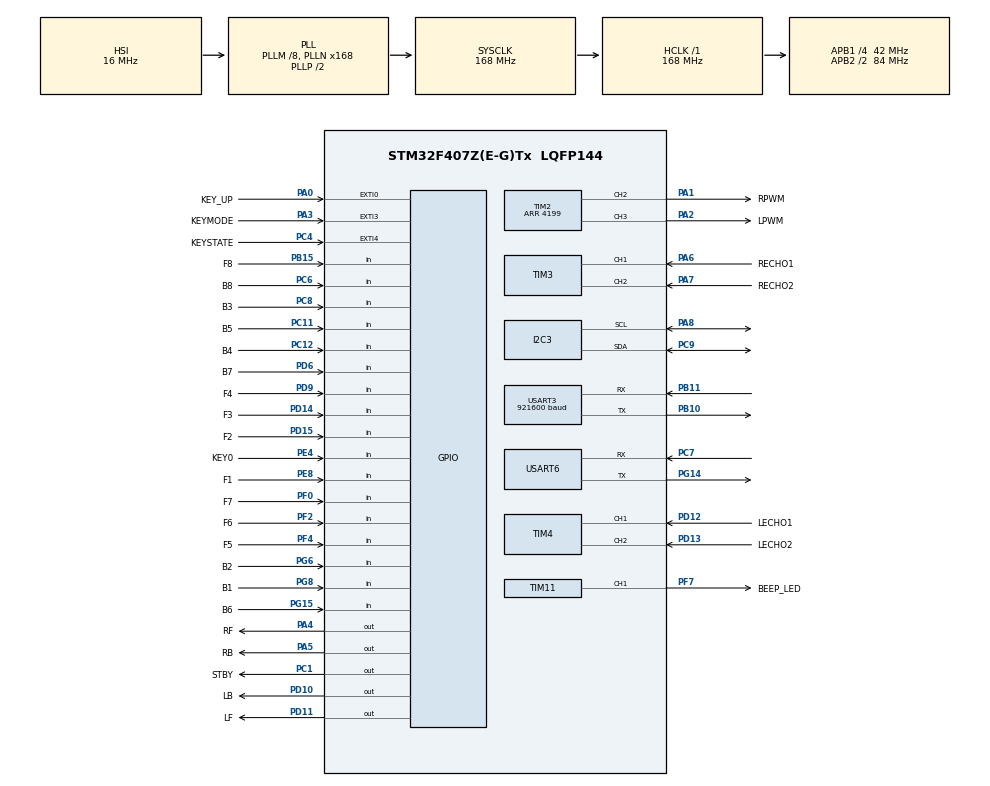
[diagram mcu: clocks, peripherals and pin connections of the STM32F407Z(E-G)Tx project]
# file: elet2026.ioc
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Dma.I2C3_TX.0.Direction=DMA_MEMORY_TO_PERIPH
Dma.I2C3_TX.0.FIFOMode=DMA_FIFOMODE_DISABLE
Dma.I2C3_TX.0.Instance=DMA1_Stream4
Dma.I2C3_TX.0.MemDataAlignment=DMA_MDATAALIGN_BYTE
Dma.I2C3_TX.0.MemInc=DMA_MINC_ENABLE
Dma.I2C3_TX.0.Mode=DMA_NORMAL
Dma.I2C3_TX.0.PeriphDataAlignment=DMA_PDATAALIGN_BYTE
Dma.I2C3_TX.0.PeriphInc=DMA_PINC_DISABLE
Dma.I2C3_TX.0.Priority=DMA_PRIORITY_LOW
Dma.Request0=I2C3_TX
Dma.Request1=USART3_RX
Dma.Request2=USART6_TX
Dma.Request3=USART6_RX
Dma.USART3_RX.1.Direction=DMA_PERIPH_TO_MEMORY
Dma.USART3_RX.1.FIFOMode=DMA_FIFOMODE_DISABLE
Dma.USART3_RX.1.Instance=DMA1_Stream1
Dma.USART3_RX.1.MemDataAlignment=DMA_MDATAALIGN_BYTE
Dma.USART3_RX.1.MemInc=DMA_MINC_ENABLE
Dma.USART3_RX.1.Mode=DMA_NORMAL
Dma.USART3_RX.1.PeriphDataAlignment=DMA_PDATAALIGN_BYTE
Dma.USART3_RX.1.PeriphInc=DMA_PINC_DISABLE
Dma.USART3_RX.1.Priority=DMA_PRIORITY_HIGH
Dma.USART6_RX.3.Direction=DMA_PERIPH_TO_MEMORY
Dma.USART6_RX.3.FIFOMode=DMA_FIFOMODE_DISABLE
Dma.USART6_RX.3.Instance=DMA2_Stream1
Dma.USART6_RX.3.MemDataAlignment=DMA_MDATAALIGN_BYTE
Dma.USART6_RX.3.MemInc=DMA_MINC_ENABLE
Dma.USART6_RX.3.Mode=DMA_NORMAL
Dma.USART6_RX.3.PeriphDataAlignment=DMA_PDATAALIGN_BYTE
Dma.USART6_RX.3.PeriphInc=DMA_PINC_DISABLE
Dma.USART6_RX.3.Priority=DMA_PRIORITY_LOW
Dma.USART6_TX.2.Direction=DMA_MEMORY_TO_PERIPH
Dma.USART6_TX.2.FIFOMode=DMA_FIFOMODE_DISABLE
Dma.USART6_TX.2.Instance=DMA2_Stream6
Dma.USART6_TX.2.MemDataAlignment=DMA_MDATAALIGN_BYTE
Dma.USART6_TX.2.MemInc=DMA_MINC_ENABLE
Dma.USART6_TX.2.Mode=DMA_NORMAL
Dma.USART6_TX.2.PeriphDataAlignment=DMA_PDATAALIGN_BYTE
Dma.USART6_TX.2.PeriphInc=DMA_PINC_DISABLE
Dma.USART6_TX.2.Priority=DMA_PRIORITY_LOW
FREERTOS.BinarySemaphores01=IMUdatadoneBinarySem,Dynamic,NULL
FREERTOS.Queues01=Controlqueue,1,6,1,Dynamic,NULL,NULL;dataToLCDQueue,1,80,1,Dynamic,NULL,NULL;paramQueue,1,68,1,Dynamic,NULL,NULL;paramtocontroltask,1,64,1,Dynamic,NULL,NULL
FREERTOS.Tasks01=defaultTask,44,256,StartDefaultTask,Default,NULL,Dynamic,NULL,NULL;PID,28,512,StartPIDTask,As external,NULL,Dynamic,NULL,NULL;controlTask,13,512,StartcontrolTask,As external,NULL,Dynamic,NULL,NULL;displayTask,8,512,StartdisplayTask,As external,NULL,Dynamic,NULL,NULL
I2C3.I2C_Mode=I2C_Fast
Mcu.Family=STM32F4
Mcu.Name=STM32F407Z(E-G)Tx
Mcu.Package=LQFP144
NVIC.DMA1_Stream1_IRQn=true\:5\:0\:false\:false\:true\:true\:false\:true
NVIC.DMA1_Stream4_IRQn=true\:5\:0\:false\:false\:true\:true\:false\:true
NVIC.DMA2_Stream1_IRQn=true\:5\:0\:false\:false\:true\:true\:false\:true
NVIC.DMA2_Stream6_IRQn=true\:5\:0\:false\:false\:true\:true\:false\:true
NVIC.EXTI0_IRQn=true\:5\:0\:false\:false\:true\:true\:true\:true
NVIC.EXTI3_IRQn=true\:5\:0\:false\:false\:true\:true\:true\:true
NVIC.EXTI4_IRQn=true\:5\:0\:false\:false\:true\:true\:true\:true
NVIC.I2C3_ER_IRQn=true\:5\:0\:false\:false\:true\:true\:true\:true
NVIC.I2C3_EV_IRQn=true\:5\:0\:false\:false\:true\:true\:true\:true
NVIC.PriorityGroup=NVIC_PRIORITYGROUP_4
NVIC.TIM6_DAC_IRQn=true\:15\:0\:false\:false\:true\:false\:false\:true
NVIC.TimeBase=TIM6_DAC_IRQn
NVIC.TimeBaseIP=TIM6
NVIC.USART3_IRQn=true\:5\:0\:false\:false\:true\:true\:true\:true
NVIC.USART6_IRQn=true\:5\:0\:false\:false\:true\:true\:true\:true
PA0-WKUP.GPIO_Label=KEY_UP
PA0-WKUP.GPIO_ModeDefaultEXTI=GPIO_MODE_IT_RISING
PA0-WKUP.GPIO_PuPd=GPIO_PULLDOWN
PA0-WKUP.Signal=GPXTI0
PA1.GPIO_Label=RPWM
PA1.Signal=S_TIM2_CH2
PA2.GPIO_Label=LPWM
PA2.Signal=S_TIM2_CH3
PA3.GPIO_Label=KEYMODE
PA3.Signal=GPXTI3
PA4.GPIO_Label=RF
PA4.Signal=GPIO_Output
PA5.GPIO_Label=RB
PA5.Signal=GPIO_Output
PA6.GPIO_Label=RECHO1
PA6.Signal=S_TIM3_CH1
PA7.GPIO_Label=RECHO2
PA7.Signal=S_TIM3_CH2
PA8.Mode=I2C
PA8.Signal=I2C3_SCL
PB10.Mode=Asynchronous
PB10.Signal=USART3_TX
PB11.Mode=Asynchronous
PB11.Signal=USART3_RX
PB15.GPIO_Label=F8
PB15.Signal=GPIO_Input
PC1.GPIO_Label=STBY
PC1.Signal=GPIO_Output
PC11.GPIO_Label=B5
PC11.Signal=GPIO_Input
PC12.GPIO_Label=B4
PC12.Signal=GPIO_Input
PC4.GPIO_Label=KEYSTATE
PC4.Signal=GPXTI4
PE4.GPIO_Label=KEY0
PE4.GPIO_PuPd=GPIO_PULLUP
PE4.Signal=GPIO_Input
PC6.GPIO_Label=B8
PC6.Signal=GPIO_Input
PC7.Mode=Asynchronous
PC7.Signal=USART6_RX
PC8.GPIO_Label=B3
PC8.Signal=GPIO_Input
PC9.Mode=I2C
PC9.Signal=I2C3_SDA
PD10.GPIO_Label=LB
PD10.Signal=GPIO_Output
PD11.GPIO_Label=LF
PD11.Signal=GPIO_Output
PD12.GPIO_Label=LECHO1
PD12.Signal=S_TIM4_CH1
PD13.GPIO_Label=LECHO2
PD13.Signal=S_TIM4_CH2
PD14.GPIO_Label=F3
PD14.Signal=GPIO_Input
PD15.GPIO_Label=F2
PD15.Signal=GPIO_Input
PD6.GPIO_Label=B7
PD6.Signal=GPIO_Input
PD9.GPIO_Label=F4
PD9.Signal=GPIO_Input
PE8.GPIO_Label=F1
PE8.Signal=GPIO_Input
PF0.GPIO_Label=F7
PF0.Signal=GPIO_Input
PF2.GPIO_Label=F6
PF2.Signal=GPIO_Input
PF4.GPIO_Label=F5
PF4.Signal=GPIO_Input
PF7.GPIO_Label=BEEP_LED
PF7.Signal=S_TIM11_CH1
PG14.Mode=Asynchronous
PG14.Signal=USART6_TX
PG15.GPIO_Label=B6
PG15.Signal=GPIO_Input
PG6.GPIO_Label=B2
PG6.Signal=GPIO_Input
PG8.GPIO_Label=B1
PG8.Signal=GPIO_Input
PH0-OSC_IN.Mode=HSE-External-Oscillator
PH0-OSC_IN.Signal=RCC_OSC_IN
PH1-OSC_OUT.Mode=HSE-External-Oscillator
PH1-OSC_OUT.Signal=RCC_OSC_OUT
ProjectManager.HeapSize=0x200
ProjectManager.StackSize=0x400
ProjectManager.TargetToolchain=MDK-ARM V5.32
RCC.48MHZClocksFreq_Value=84000000
RCC.AHBFreq_Value=168000000
RCC.APB1CLKDivider=RCC_HCLK_DIV4
RCC.APB1Freq_Value=42000000
RCC.APB1TimFreq_Value=84000000
RCC.APB2CLKDivider=RCC_HCLK_DIV2
RCC.APB2Freq_Value=84000000
RCC.APB2TimFreq_Value=168000000
RCC.CortexFreq_Value=168000000
RCC.HCLKFreq_Value=168000000
RCC.HSE_VALUE=8000000
RCC.HSI_VALUE=16000000
RCC.LSE_VALUE=32768
RCC.PLLM=8
RCC.PLLN=168
RCC.SYSCLKFreq_VALUE=168000000
RCC.SYSCLKSource=RCC_SYSCLKSOURCE_PLLCLK
RCC.VCOOutputFreq_Value=336000000
SH.S_TIM11_CH1.0=TIM11_CH1,PWM Generation1 CH1
SH.S_TIM2_CH2.0=TIM2_CH2,PWM Generation2 CH2
SH.S_TIM2_CH3.0=TIM2_CH3,PWM Generation3 CH3
SH.S_TIM3_CH1.0=TIM3_CH1,Encoder_Interface
SH.S_TIM3_CH2.0=TIM3_CH2,Encoder_Interface
SH.S_TIM4_CH1.0=TIM4_CH1,Encoder_Interface
SH.S_TIM4_CH2.0=TIM4_CH2,Encoder_Interface
TIM11.Channel=TIM_CHANNEL_1
TIM2.Channel-PWM\ Generation2\ CH2=TIM_CHANNEL_2
TIM2.Channel-PWM\ Generation3\ CH3=TIM_CHANNEL_3
TIM2.Period=4199
TIM3.EncoderMode=TIM_ENCODERMODE_TI12
TIM4.EncoderMode=TIM_ENCODERMODE_TI12
USART3.BaudRate=921600
USART3.VirtualMode=VM_ASYNC
USART6.VirtualMode=VM_ASYNC
VP_FREERTOS_VS_CMSIS_V2.Mode=CMSIS_V2
VP_SYS_VS_tim6.Mode=TIM6
VP_TIM11_VS_ClockSourceINT.Mode=Enable_Timer
VP_TIM2_VS_ClockSourceINT.Mode=Internal
board=custom

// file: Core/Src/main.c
/* USER CODE BEGIN Header */
/**
  ******************************************************************************
  * @file           : main.c
  * @brief          : Main program body
  ******************************************************************************
  * @attention
  *
  * <h2><center>&copy; Copyright (c) 2026 STMicroelectronics.
  * All rights reserved.</center></h2>
  *
  * This software component is licensed by ST under Ultimate Liberty license
  * SLA0044, the "License"; You may not use this file except in compliance with
  * the License. You may obtain a copy of the License at:
  *                             www.st.com/SLA0044
  *
  ******************************************************************************
  */
/* USER CODE END Header */
#include "main.h"
#include "cmsis_os.h"
#include "dma.h"
#include "i2c.h"
#include "tim.h"
#include "usart.h"
#include "gpio.h"

void SystemClock_Config(void);
void MX_FREERTOS_Init(void);

int main(void)
{

  /* MCU Configuration--------------------------------------------------------*/

  /* Reset of all peripherals, Initializes the Flash interface and the Systick. */
  HAL_Init();

  /* Configure the system clock */
  SystemClock_Config();

  /* Initialize all configured peripherals */
  MX_GPIO_Init();
  MX_DMA_Init();
  MX_TIM3_Init();
  MX_TIM4_Init();
  MX_TIM2_Init();
  MX_I2C3_Init();
  MX_USART3_UART_Init();
  MX_TIM11_Init();
  MX_USART6_UART_Init();

  /* Init scheduler */
  osKernelInitialize();  /* Call init function for freertos objects (in freertos.c) */
  MX_FREERTOS_Init();
  /* Start scheduler */
  osKernelStart();

  /* We should never get here as control is now taken by the scheduler */
  /* Infinite loop */
  while (1)
  {

  }
}

void SystemClock_Config(void)
{
  RCC_OscInitTypeDef RCC_OscInitStruct = {0};
  RCC_ClkInitTypeDef RCC_ClkInitStruct = {0};

  /** Configure the main internal regulator output voltage
  */
  __HAL_RCC_PWR_CLK_ENABLE();
  __HAL_PWR_VOLTAGESCALING_CONFIG(PWR_REGULATOR_VOLTAGE_SCALE1);
  /** Initializes the RCC Oscillators according to the specified parameters
  * in the RCC_OscInitTypeDef structure.
  */
  RCC_OscInitStruct.OscillatorType = RCC_OSCILLATORTYPE_HSI;
  RCC_OscInitStruct.HSIState = RCC_HSI_ON;
  RCC_OscInitStruct.HSICalibrationValue = RCC_HSICALIBRATION_DEFAULT;
  RCC_OscInitStruct.PLL.PLLState = RCC_PLL_ON;
  RCC_OscInitStruct.PLL.PLLSource = RCC_PLLSOURCE_HSI;
  RCC_OscInitStruct.PLL.PLLM = 8;
  RCC_OscInitStruct.PLL.PLLN = 168;
  RCC_OscInitStruct.PLL.PLLP = RCC_PLLP_DIV2;
  RCC_OscInitStruct.PLL.PLLQ = 4;
  if (HAL_RCC_OscConfig(&RCC_OscInitStruct) != HAL_OK)
  {
    Error_Handler();
  }
  /** Initializes the CPU, AHB and APB buses clocks
  */
  RCC_ClkInitStruct.ClockType = RCC_CLOCKTYPE_HCLK|RCC_CLOCKTYPE_SYSCLK
                              |RCC_CLOCKTYPE_PCLK1|RCC_CLOCKTYPE_PCLK2;
  RCC_ClkInitStruct.SYSCLKSource = RCC_SYSCLKSOURCE_PLLCLK;
  RCC_ClkInitStruct.AHBCLKDivider = RCC_SYSCLK_DIV1;
  RCC_ClkInitStruct.APB1CLKDivider = RCC_HCLK_DIV4;
  RCC_ClkInitStruct.APB2CLKDivider = RCC_HCLK_DIV2;

  if (HAL_RCC_ClockConfig(&RCC_ClkInitStruct, FLASH_LATENCY_5) != HAL_OK)
  {
    Error_Handler();
  }
}

void HAL_TIM_PeriodElapsedCallback(TIM_HandleTypeDef *htim)
{
  if (htim->Instance == TIM6) {
    HAL_IncTick();
  }
}

void Error_Handler(void)
{
  __disable_irq();
  while (1)
  {
  }
}

/************************ (C) COPYRIGHT STMicroelectronics *****END OF FILE****/

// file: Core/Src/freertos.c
/* USER CODE BEGIN Header */
/**
  ******************************************************************************
  * File Name          : freertos.c
  * Description        : Code for freertos applications
  ******************************************************************************
  * @attention
  *
  * <h2><center>&copy; Copyright (c) 2026 STMicroelectronics.
  * All rights reserved.</center></h2>
  *
  * This software component is licensed by ST under Ultimate Liberty license
  * SLA0044, the "License"; You may not use this file except in compliance with
  * the License. You may obtain a copy of the License at:
  *                             www.st.com/SLA0044
  *
  ******************************************************************************
  */
/* USER CODE END Header */

#include "FreeRTOS.h"
#include "task.h"
#include "main.h"
#include "cmsis_os.h"

/* USER CODE BEGIN Includes */
#include "imu_task.h"
#include "encoder.h"
/* USER CODE END Includes */

/* Definitions for defaultTask */
osThreadId_t defaultTaskHandle;
const osThreadAttr_t defaultTask_attributes = {
  .name = "defaultTask",
  .stack_size = 256 * 4,
  .priority = (osPriority_t) osPriorityHigh4,
};
/* Definitions for PID */
osThreadId_t PIDHandle;
const osThreadAttr_t PID_attributes = {
  .name = "PID",
  .stack_size = 512 * 4,
  .priority = (osPriority_t) osPriorityNormal4,
};
/* Definitions for controlTask */
osThreadId_t controlTaskHandle;
const osThreadAttr_t controlTask_attributes = {
  .name = "controlTask",
  .stack_size = 512 * 4,
  .priority = (osPriority_t) osPriorityLow5,
};
/* Definitions for displayTask */
osThreadId_t displayTaskHandle;
const osThreadAttr_t displayTask_attributes = {
  .name = "displayTask",
  .stack_size = 512 * 4,
  .priority = (osPriority_t) osPriorityLow,
};
/* Definitions for Controlqueue */
osMessageQueueId_t ControlqueueHandle;
const osMessageQueueAttr_t Controlqueue_attributes = {
  .name = "Controlqueue"
};
/* Definitions for dataToLCDQueue */
osMessageQueueId_t dataToLCDQueueHandle;
const osMessageQueueAttr_t dataToLCDQueue_attributes = {
  .name = "dataToLCDQueue"
};
/* Definitions for paramQueue */
osMessageQueueId_t paramQueueHandle;
const osMessageQueueAttr_t paramQueue_attributes = {
  .name = "paramQueue"
};
/* Definitions for paramtocontroltask */
osMessageQueueId_t paramtocontroltaskHandle;
const osMessageQueueAttr_t paramtocontroltask_attributes = {
  .name = "paramtocontroltask"
};
/* Definitions for IMUdatadoneBinarySem */
osSemaphoreId_t IMUdatadoneBinarySemHandle;
const osSemaphoreAttr_t IMUdatadoneBinarySem_attributes = {
  .name = "IMUdatadoneBinarySem"
};

void StartDefaultTask(void *argument);
extern void StartPIDTask(void *argument);
extern void StartcontrolTask(void *argument);
extern void StartdisplayTask(void *argument);

void MX_FREERTOS_Init(void); /* (MISRA C 2004 rule 8.1) */

void MX_FREERTOS_Init(void) {

  /* Create the semaphores(s) */
  /* creation of IMUdatadoneBinarySem */
  IMUdatadoneBinarySemHandle = osSemaphoreNew(1, 1, &IMUdatadoneBinarySem_attributes);

  /* USER CODE BEGIN RTOS_SEMAPHORES */
  /* 确保初�?�为 0：PID 只能�? USART1 RX DMA 完成中断释放后运�? */
  (void)osSemaphoreAcquire(IMUdatadoneBinarySemHandle, 0U);
  /* USER CODE END RTOS_SEMAPHORES */

  /* Create the queue(s) */
  /* creation of Controlqueue */
  ControlqueueHandle = osMessageQueueNew (1, 6, &Controlqueue_attributes);

  /* creation of dataToLCDQueue */
  dataToLCDQueueHandle = osMessageQueueNew (1, 80, &dataToLCDQueue_attributes);

  /* creation of paramQueue */
  paramQueueHandle = osMessageQueueNew (1, 68, &paramQueue_attributes);

  /* creation of paramtocontroltask */
  paramtocontroltaskHandle = osMessageQueueNew (1, 64, &paramtocontroltask_attributes);

  /* Create the thread(s) */
  /* creation of defaultTask */
  defaultTaskHandle = osThreadNew(StartDefaultTask, NULL, &defaultTask_attributes);

  /* creation of PID */
  PIDHandle = osThreadNew(StartPIDTask, NULL, &PID_attributes);

  /* creation of controlTask */
  controlTaskHandle = osThreadNew(StartcontrolTask, NULL, &controlTask_attributes);

  /* creation of displayTask */
  displayTaskHandle = osThreadNew(StartdisplayTask, NULL, &displayTask_attributes);

}

/* USER CODE BEGIN Header_StartDefaultTask */
/**
  * @brief  初始化任务：完成 IMU 初始化后永久挂起，不再参与调�?
  * @param  argument: Not used
  * @retval None
  */
/* USER CODE END Header_StartDefaultTask */
void StartDefaultTask(void *argument)
{
  /* USER CODE BEGIN StartDefaultTask */
  (void)argument;

  /* 先启�? TIM3/TIM4 正交编码器，初始 CNT=6554�?16 位�?�量�? 1/10�? */
  (void)Encoder_Init();

  /* 初始�? ATK-MS901M：配�? 921600 / 250 Hz / 九轴，并启动 USART1 RX DMA */

  /*
   * 初始化失败时每秒重试�?次；重试期间 osDelay 让出 CPU，controlTask 仍可运行�?
   * 成功后再永久挂起，把 CPU 全部留给 PID/controlTask�?
   */
  while (IMU_Init() == 0U)
  {
    (void)osDelay(1000U);
  }

  /*
   * defaultTask 优先�? 44，只负责�?次�?�初始化�?
   * 初始化完成后必须永久挂起，否则会持续占用 CPU，PID/controlTask 无法运行�?
   * 用循环包住挂起：即使被意�? vTaskResume，也会立刻再次挂起�??
   */
  for (;;)
  {
    vTaskSuspend(NULL);
  }
  /* USER CODE END StartDefaultTask */
}

/************************ (C) COPYRIGHT STMicroelectronics *****END OF FILE****/
